# Capacitive_Touch_IO_0_2 register map
Vendor: Texas Instruments
Peripheral module from a debugger description file (folder msp430).
Registers are 16-bit, read-write, reset 0x0 unless marked. A register's access mark holds for its fields unless they carry their own. Offsets are as the file gives them; lines under a group give offsets from that group; [hi:lo] are bit positions; {n}, {i} and the like mark numbered series; 'fields as' and 'values as' point back to an identical list; <NAME> marks a mode.

## Capacitive_Touch_IO_0
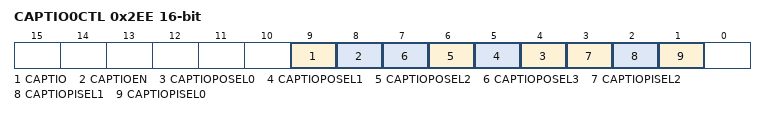
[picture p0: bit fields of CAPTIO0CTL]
0x2EE CAPTIO0CTL — Capacitive_Touch_IO 0 control register
  [9] CAPTIO — CapTouchIO state
  [8] CAPTIOEN — CapTouchIO Enable
  [n+4] CAPTIOPOSEL{n} (n=0..3) — CapTouchIO Port Select Bit: {n}
  [3] CAPTIOPISEL2 — CapTouchIO Pin Select Bit: 2
  [2] CAPTIOPISEL1 — CapTouchIO Pin Select Bit: 1
  [1] CAPTIOPISEL0 — CapTouchIO Pin Select Bit: 0
